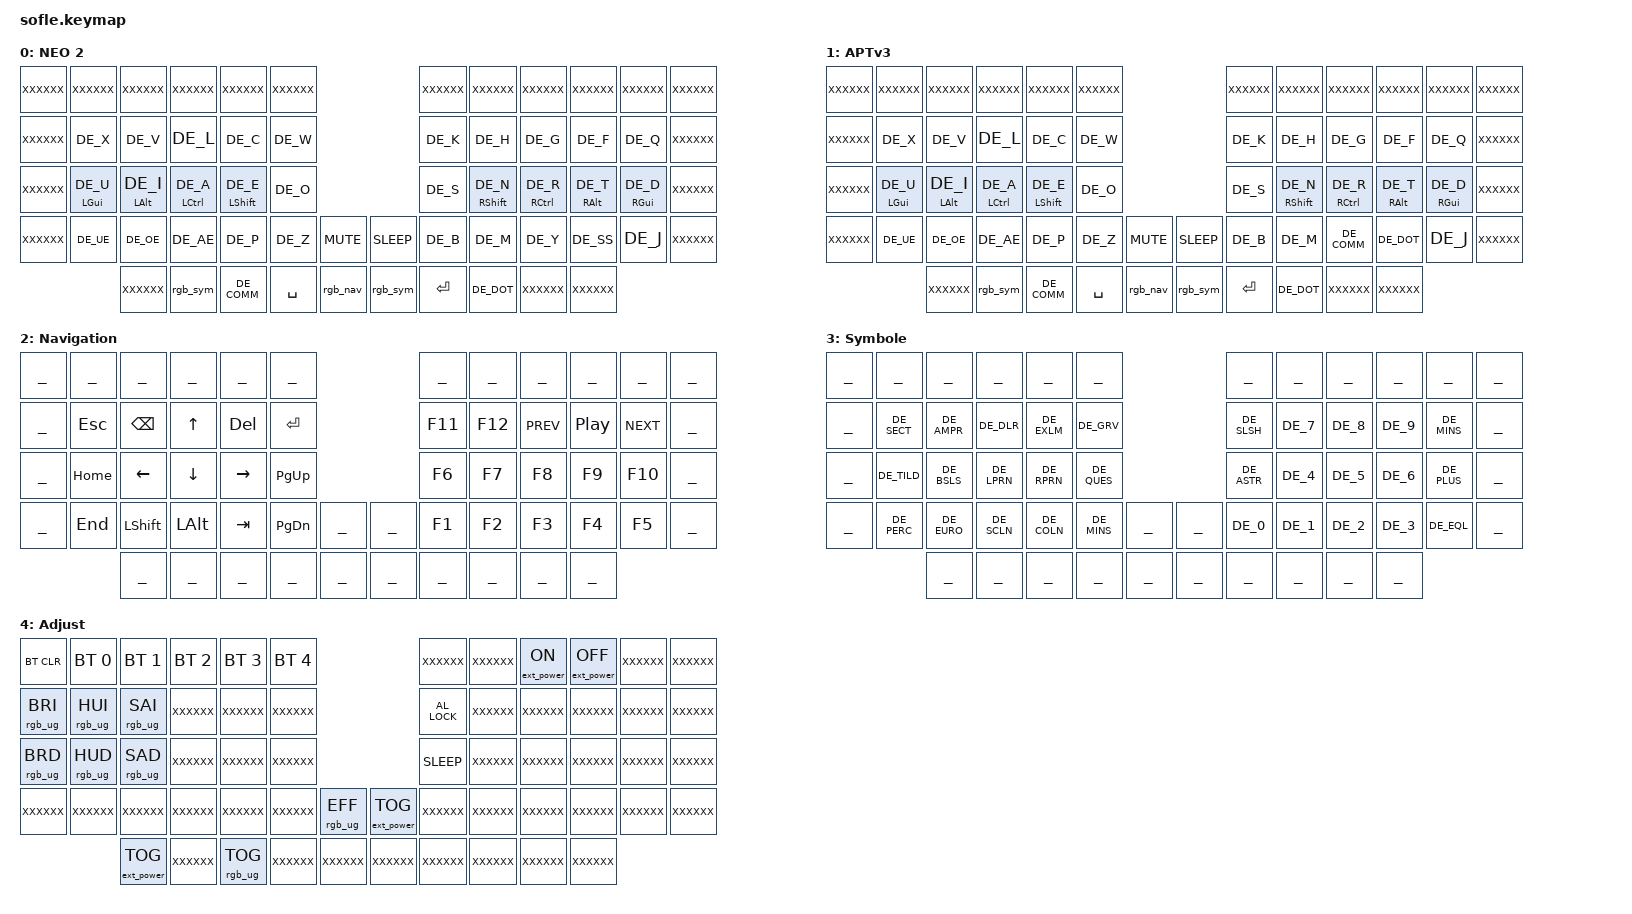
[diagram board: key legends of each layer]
 /*
 * Copyright (c) 2020 The ZMK Contributors
 *
 * SPDX-License-Identifier: MIT
 * NEO 2
 */


#include <behaviors.dtsi>
#include <dt-bindings/zmk/keys.h>
#include <dt-bindings/zmk/bt.h>
#include <dt-bindings/zmk/rgb.h>
#include <dt-bindings/zmk/ext_power.h>
#include "CustomFunction/util.h"
#include "CustomFunction/define_keys.dtsi"
#include "CustomFunction/macro.keymap"
#include "CustomFunction/taps.keymap"

#define NEO 0
#define APT 1
#define NAV 2
#define SYM 3
#define ADJ 4

/ {

   // Activate ADJUST layer by pressing raise and lower
    conditional_layers {
        compatible = "zmk,conditional-layers";
        adjust_layer {
            if-layers = <SYM NAV>;
            then-layer = <ADJ>;
        };
    };

    keymap {
        compatible = "zmk,keymap";
        neo_layer {
            label = "NEO 2";
            bindings = <
// ╭─────────────────────┬─────────────────────┬─────────────────────┬─────────────────────┬─────────────────────┬─────────────────────╮                                             ╭─────────────────────┬─────────────────────┬─────────────────────┬─────────────────────┬─────────────────────┬─────────────────────╮
           XXXXXX                XXXXXX                XXXXXX                XXXXXX                XXXXXX                XXXXXX                                                              XXXXXX                XXXXXX                 XXXXXX                XXXXXX              XXXXXX                 XXXXXX
// ├─────────────────────┼─────────────────────┼─────────────────────┼─────────────────────┼─────────────────────┼─────────────────────┤                                             ├─────────────────────┼─────────────────────┼─────────────────────┼─────────────────────┼─────────────────────┼─────────────────────┤
           XXXXXX               &kp DE_X              &kp DE_V              &kp DE_L              &kp DE_C              &kp DE_W                                                            &kp DE_K              &kp DE_H              &kp DE_G              &kp DE_F              &kp DE_Q               XXXXXX
// ├─────────────────────┼─────────────────────┼─────────────────────┼─────────────────────┼─────────────────────┼─────────────────────┤                                             ├─────────────────────┼─────────────────────┼─────────────────────┼─────────────────────┼─────────────────────┼─────────────────────┤
           XXXXXX           &hm_l LGUI DE_U         &hm_l LALT DE_I      &hm_l LCTRL DE_A      &hm_l LSHIFT DE_E        &kp DE_O                                                            &kp DE_S          &hm_r RSHIFT DE_N      &hm_r RCTRL DE_R      &hm_r RALT DE_T       &hm_r RGUI DE_D           XXXXXX
// ├─────────────────────┼─────────────────────┼─────────────────────┼─────────────────────┼─────────────────────┼─────────────────────┤─────────────────────╮ ╭─────────────────────┼─────────────────────┼─────────────────────┼─────────────────────┼─────────────────────┼─────────────────────┤─────────────────────┤
           XXXXXX               &kp DE_UE             &kp DE_OE             &kp DE_AE             &kp DE_P              &kp DE_Z              &kp C_MUTE             &kp C_SLEEP            &kp DE_B              &kp DE_M              &kp DE_Y              &kp DE_SS             &kp DE_J               XXXXXX
// ╰─────────────────────┴─────────────────────┼─────────────────────┼─────────────────────┼─────────────────────┼─────────────────────┤─────────────────────┤ ├─────────────────────┼─────────────────────┼─────────────────────┼─────────────────────┼─────────────────────┼─────────────────────┴─────────────────────╯
                                                       XXXXXX                &rgb_sym             &kp DE_COMM           &kp SPACE             &rgb_nav                &rgb_sym               &kp RET             &kp DE_DOT               XXXXXX               XXXXXX
//                                             ╰─────────────────────┴─────────────────────┴─────────────────────┴─────────────────────┴─────────────────────╯ ╰─────────────────────┴─────────────────────┴─────────────────────┴─────────────────────┴─────────────────────╯
            >;
            sensor-bindings = <&inc_dec_kp C_VOL_UP C_VOL_DN &inc_dec_kp PG_UP PG_DN>;
        };                                        
// -------------------------------------------------------------------------------------------------------------------------------------------------------------------------------------------------------------------------------------------------
        apt_layer {
            label = "APTv3";
            bindings = <
// ╭─────────────────────┬─────────────────────┬─────────────────────┬─────────────────────┬─────────────────────┬─────────────────────╮                                             ╭─────────────────────┬─────────────────────┬─────────────────────┬─────────────────────┬─────────────────────┬─────────────────────╮
           XXXXXX                XXXXXX                XXXXXX                XXXXXX                XXXXXX                XXXXXX                                                              XXXXXX                XXXXXX                 XXXXXX                XXXXXX              XXXXXX                 XXXXXX
// ├─────────────────────┼─────────────────────┼─────────────────────┼─────────────────────┼─────────────────────┼─────────────────────┤                                             ├─────────────────────┼─────────────────────┼─────────────────────┼─────────────────────┼─────────────────────┼─────────────────────┤
           XXXXXX               &kp DE_X              &kp DE_V              &kp DE_L              &kp DE_C              &kp DE_W                                                            &kp DE_K              &kp DE_H              &kp DE_G              &kp DE_F              &kp DE_Q               XXXXXX
// ├─────────────────────┼─────────────────────┼─────────────────────┼─────────────────────┼─────────────────────┼─────────────────────┤                                             ├─────────────────────┼─────────────────────┼─────────────────────┼─────────────────────┼─────────────────────┼─────────────────────┤
           XXXXXX           &hm_l LGUI DE_U         &hm_l LALT DE_I      &hm_l LCTRL DE_A      &hm_l LSHIFT DE_E        &kp DE_O                                                            &kp DE_S          &hm_r RSHIFT DE_N      &hm_r RCTRL DE_R      &hm_r RALT DE_T       &hm_r RGUI DE_D           XXXXXX
// ├─────────────────────┼─────────────────────┼─────────────────────┼─────────────────────┼─────────────────────┼─────────────────────┤─────────────────────╮ ╭─────────────────────┼─────────────────────┼─────────────────────┼─────────────────────┼─────────────────────┼─────────────────────┤─────────────────────┤
           XXXXXX               &kp DE_UE            &kp DE_OE             &kp DE_AE              &kp DE_P              &kp DE_Z              &kp C_MUTE             &kp C_SLEEP            &kp DE_B              &kp DE_M             &kp DE_COMM           &kp DE_DOT             &kp DE_J               XXXXXX
// ╰─────────────────────┴─────────────────────┼─────────────────────┼─────────────────────┼─────────────────────┼─────────────────────┤─────────────────────┤ ├─────────────────────┼─────────────────────┼─────────────────────┼─────────────────────┼─────────────────────┼─────────────────────┴─────────────────────╯
                                                       XXXXXX                &rgb_sym             &kp DE_COMM           &kp SPACE             &rgb_nav                &rgb_sym               &kp RET             &kp DE_DOT               XXXXXX               XXXXXX
//                                             ╰─────────────────────┴─────────────────────┴─────────────────────┴─────────────────────┴─────────────────────╯ ╰─────────────────────┴─────────────────────┴─────────────────────┴─────────────────────┴─────────────────────╯
            >;
            sensor-bindings = <&inc_dec_kp C_VOL_UP C_VOL_DN &inc_dec_kp PG_UP PG_DN>;
        };                       
// -------------------------------------------------------------------------------------------------------------------------------------------------------------------------------------------------------------------------------------------------
        nav_layer {
            label = "Navigation";
            bindings = <
// ╭─────────────────────┬─────────────────────┬─────────────────────┬─────────────────────┬─────────────────────┬─────────────────────╮                                             ╭─────────────────────┬─────────────────────┬─────────────────────┬─────────────────────┬─────────────────────┬─────────────────────╮
           ______                ______                ______                ______                ______                ______                                                               ______               ______                 ______                ______               ______                ______
// ├─────────────────────┼─────────────────────┼─────────────────────┼─────────────────────┼─────────────────────┼─────────────────────┤                                             ├─────────────────────┼─────────────────────┼─────────────────────┼─────────────────────┼─────────────────────┼─────────────────────┤
           ______                &kp ESC              &kp BSPC                &kp UP               &kp DEL              &kp RET                                                             &kp F11               &kp F12              &kp C_PREV         &kp C_PLAY_PAUSE         &kp C_NEXT              ______
// ├─────────────────────┼─────────────────────┼─────────────────────┼─────────────────────┼─────────────────────┼─────────────────────┤                                             ├─────────────────────┼─────────────────────┼─────────────────────┼─────────────────────┼─────────────────────┼─────────────────────┤
           ______               &kp HOME              &kp LEFT               &kp DOWN             &kp RIGHT           &kp PAGE_UP                                                            &kp F6               &kp F7                 &kp F8                &kp F9                &kp F10               ______
// ├─────────────────────┼─────────────────────┼─────────────────────┼─────────────────────┼─────────────────────┼─────────────────────┤─────────────────────╮ ╭─────────────────────┼─────────────────────┼─────────────────────┼─────────────────────┼─────────────────────┼─────────────────────┼─────────────────────┤
           ______                &kp END             &kp LSHIFT              &kp LALT              &kp TAB           &kp PAGE_DOWN              ______                  ______               &kp F1               &kp F2                 &kp F3                &kp F4                &kp F5                ______
// ╰─────────────────────┴─────────────────────┼─────────────────────┼─────────────────────┼─────────────────────┼─────────────────────┤─────────────────────┤ ├─────────────────────┼─────────────────────┼─────────────────────┼─────────────────────┼─────────────────────┼─────────────────────┴─────────────────────╯
                                                        ______                ______               ______                ______                 ______                  ______                ______                ______                ______                ______
//                                             ╰─────────────────────┴─────────────────────┴─────────────────────┴─────────────────────┴─────────────────────╯ ╰─────────────────────┴─────────────────────┴─────────────────────┴─────────────────────┴─────────────────────╯
            >;
            sensor-bindings = <&inc_dec_cp C_BRI_UP C_BRI_DN &inc_dec_kp PG_UP PG_DN>;
        };               
// -------------------------------------------------------------------------------------------------------------------------------------------------------------------------------------------------------------------------------------------------
        sym_layer {
            label = "Symbole";
            bindings = <
// ╭─────────────────────┬─────────────────────┬─────────────────────┬─────────────────────┬─────────────────────┬─────────────────────╮                                             ╭─────────────────────┬─────────────────────┬─────────────────────┬─────────────────────┬─────────────────────┬─────────────────────╮
           ______                ______                ______                ______                ______                ______                                                               ______               ______                 ______                ______               ______                ______
// ├─────────────────────┼─────────────────────┼─────────────────────┼─────────────────────┼─────────────────────┼─────────────────────┤                                             ├─────────────────────┼─────────────────────┼─────────────────────┼─────────────────────┼─────────────────────┼─────────────────────┤
           ______              &kp DE_SECT            &kp DE_AMPR           &kp DE_DLR            &kp DE_EXLM          &kp DE_GRV                                                         &kp DE_SLSH             &kp DE_7              &kp DE_8              &kp DE_9             &kp DE_MINS             ______
// ├─────────────────────┼─────────────────────┼─────────────────────┼─────────────────────┼─────────────────────┼─────────────────────┤                                             ├─────────────────────┼─────────────────────┼─────────────────────┼─────────────────────┼─────────────────────┼─────────────────────┤
           ______              &kp DE_TILD            &kp DE_BSLS           &kp DE_LPRN           &kp DE_RPRN          &kp DE_QUES                                                         &kp DE_ASTR            &kp DE_4              &kp DE_5              &kp DE_6             &kp DE_PLUS             ______
// ├─────────────────────┼─────────────────────┼─────────────────────┼─────────────────────┼─────────────────────┼─────────────────────┤─────────────────────╮ ╭─────────────────────┼─────────────────────┼─────────────────────┼─────────────────────┼─────────────────────┼─────────────────────┼─────────────────────┤
           ______             &kp DE_PERC            &kp DE_EURO            &kp DE_SCLN           &kp DE_COLN          &kp DE_MINS              ______                  ______              &kp DE_0              &kp DE_1              &kp DE_2              &kp DE_3              &kp DE_EQL             ______
// ╰─────────────────────┴─────────────────────┼─────────────────────┼─────────────────────┼─────────────────────┼─────────────────────┤─────────────────────┤ ├─────────────────────┼─────────────────────┼─────────────────────┼─────────────────────┼─────────────────────┼─────────────────────┴─────────────────────╯
                                                        ______                ______               ______                ______                ______                  ______                 ______                ______                ______                ______
//                                             ╰─────────────────────┴─────────────────────┴─────────────────────┴─────────────────────┴─────────────────────╯ ╰─────────────────────┴─────────────────────┴─────────────────────┴─────────────────────┴─────────────────────╯
            >;
            sensor-bindings = <&inc_dec_cp C_BRI_UP C_BRI_DN &inc_dec_kp PG_UP PG_DN>;
        };
// -------------------------------------------------------------------------------------------------------------------------------------------------------------------------------------------------------------------------------------------------
        adj_layer {
            label = "Adjust";
            bindings = <
// ╭─────────────────────┬─────────────────────┬─────────────────────┬─────────────────────┬─────────────────────┬─────────────────────╮                                             ╭─────────────────────┬─────────────────────┬─────────────────────┬─────────────────────┬─────────────────────┬─────────────────────╮
         &bt BT_CLR           &bt BT_SEL 0           &bt BT_SEL 1          &bt BT_SEL 2          &bt BT_SEL 3          &bt BT_SEL 4                                                           XXXXXX                XXXXXX          &ext_power EP_ON       &ext_power EP_OFF          XXXXXX                XXXXXX
// ├─────────────────────┼─────────────────────┼─────────────────────┼─────────────────────┼─────────────────────┼─────────────────────┤                                             ├─────────────────────┼─────────────────────┼─────────────────────┼─────────────────────┼─────────────────────┼─────────────────────┤
       &rgb_ug RGB_BRI       &rgb_ug RGB_HUI       &rgb_ug RGB_SAI            XXXXXX               XXXXXX                XXXXXX                                                           &kp C_AL_LOCK             XXXXXX                XXXXXX               XXXXXX                 XXXXXX                XXXXXX
// ├─────────────────────┼─────────────────────┼─────────────────────┼─────────────────────┼─────────────────────┼─────────────────────┤                                             ├─────────────────────┼─────────────────────┼─────────────────────┼─────────────────────┼─────────────────────┼─────────────────────┤
       &rgb_ug RGB_BRD       &rgb_ug RGB_HUD       &rgb_ug RGB_SAD            XXXXXX               XXXXXX                XXXXXX                                                            &kp C_SLEEP              XXXXXX                XXXXXX               XXXXXX                 XXXXXX                XXXXXX
// ├─────────────────────┼─────────────────────┼─────────────────────┼─────────────────────┼─────────────────────┼─────────────────────┤─────────────────────╮ ╭─────────────────────┼─────────────────────┼─────────────────────┼─────────────────────┼─────────────────────┼─────────────────────┼─────────────────────┤
            XXXXXX               XXXXXX                XXXXXX                 XXXXXX               XXXXXX                XXXXXX            &rgb_ug RGB_EFF        &ext_power EP_TOG           XXXXXX                XXXXXX                XXXXXX               XXXXXX                 XXXXXX                XXXXXX
// ╰─────────────────────┴─────────────────────┼─────────────────────┼─────────────────────┼─────────────────────┼─────────────────────┤─────────────────────┤ ├─────────────────────┼─────────────────────┼─────────────────────┼─────────────────────┼─────────────────────┼─────────────────────┴─────────────────────╯
                                                  &ext_power EP_TOG           XXXXXX           &rgb_ug RGB_TOG           XXXXXX                XXXXXX                  XXXXXX                 XXXXXX                XXXXXX                XXXXXX               XXXXXX
//                                             ╰─────────────────────┴─────────────────────┴─────────────────────┴─────────────────────┴─────────────────────╯ ╰─────────────────────┴─────────────────────┴─────────────────────┴─────────────────────┴─────────────────────╯
            >;
            sensor-bindings = <&inc_dec_kp C_VOL_UP C_VOL_DN &inc_dec_kp PG_UP PG_DN>;
        };
     };
};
